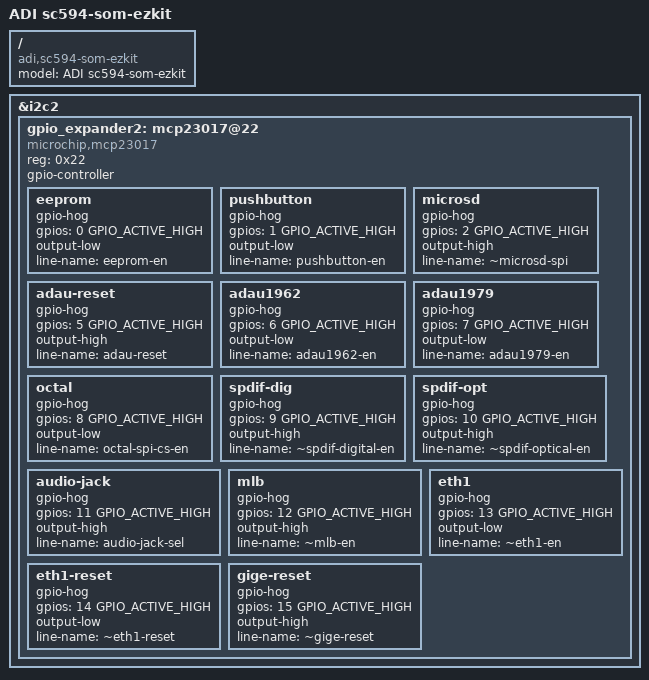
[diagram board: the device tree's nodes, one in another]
// SPDX-License-Identifier: GPL-2.0-or-later
/*
 * (C) Copyright 2022 - Analog Devices, Inc.
 *
 * Written and/or maintained by Timesys Corporation
 *
 * Contact: Nathan Barrett-Morrison <nathan.morrison@timesys.com>
 * Contact: Greg Malysa <greg.malysa@timesys.com>
 */

/dts-v1/;

#include "sc594-som.dtsi"

/ {
	model = "ADI sc594-som-ezkit";
	compatible = "adi,sc594-som-ezkit", "adi,sc59x";
};

&i2c2{
	gpio_expander2: mcp23017@22 {
		compatible = "microchip,mcp23017";
		reg = <0x22>;
		gpio-controller;
		#gpio-cells = <2>;
		bootph-all;

		eeprom {
			gpio-hog;
			gpios = <0 GPIO_ACTIVE_HIGH>;
			output-low;
			line-name = "eeprom-en";
			bootph-all;
		};

		pushbutton {
			gpio-hog;
			gpios = <1 GPIO_ACTIVE_HIGH>;
			output-low;
			line-name = "pushbutton-en";
			bootph-all;
		};

		microsd {
			gpio-hog;
			gpios = <2 GPIO_ACTIVE_HIGH>;
			output-high;
			line-name = "~microsd-spi";
			bootph-all;
		};

		adau-reset {
			gpio-hog;
			gpios = <5 GPIO_ACTIVE_HIGH>;
			output-high;
			line-name = "adau-reset";
			bootph-all;
		};

		adau1962 {
			gpio-hog;
			gpios = <6 GPIO_ACTIVE_HIGH>;
			output-low;
			line-name = "adau1962-en";
			bootph-all;
		};

		adau1979 {
			gpio-hog;
			gpios = <7 GPIO_ACTIVE_HIGH>;
			output-low;
			line-name = "adau1979-en";
			bootph-all;
		};

		octal {
			gpio-hog;
			gpios = <8 GPIO_ACTIVE_HIGH>;
			output-low;
			line-name = "octal-spi-cs-en";
			bootph-all;
		};

		spdif-dig {
			gpio-hog;
			gpios = <9 GPIO_ACTIVE_HIGH>;
			output-high;
			line-name = "~spdif-digital-en";
			bootph-all;
		};

		spdif-opt {
			gpio-hog;
			gpios = <10 GPIO_ACTIVE_HIGH>;
			output-high;
			line-name = "~spdif-optical-en";
			bootph-all;
		};

		audio-jack {
			gpio-hog;
			gpios = <11 GPIO_ACTIVE_HIGH>;
			output-high;
			line-name = "audio-jack-sel";
			bootph-all;
		};

		mlb {
			gpio-hog;
			gpios = <12 GPIO_ACTIVE_HIGH>;
			output-high;
			line-name = "~mlb-en";
			bootph-all;
		};

		eth1 {
			gpio-hog;
			gpios = <13 GPIO_ACTIVE_HIGH>;
			output-low;
			line-name = "~eth1-en";
			bootph-all;
		};

		eth1-reset {
			gpio-hog;
			gpios = <14 GPIO_ACTIVE_HIGH>;
			/*
			 * USB0 lines are shared with Eth1 so  Eth PHY must be held in reset
			 * when using the USB
			 */
			output-low;
			line-name = "~eth1-reset";
			bootph-all;
		};

		gige-reset {
			gpio-hog;
			gpios = <15 GPIO_ACTIVE_HIGH>;
			output-high;
			line-name = "~gige-reset";
			bootph-all;
		};
	};
};
